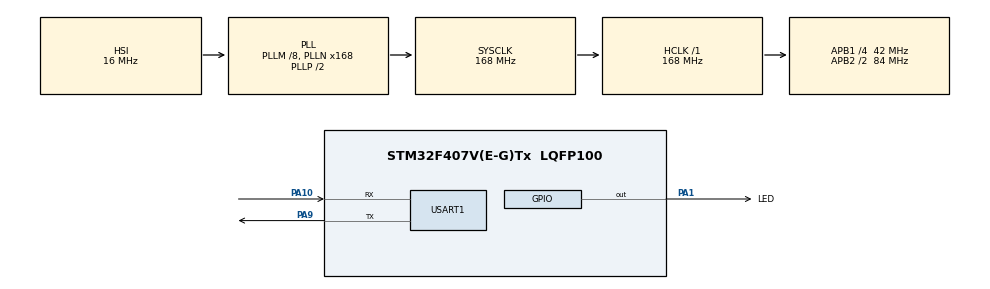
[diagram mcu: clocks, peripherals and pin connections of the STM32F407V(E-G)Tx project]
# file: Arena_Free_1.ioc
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Dma.Request0=USART1_RX
Dma.Request1=USART1_TX
Dma.USART1_RX.0.Direction=DMA_PERIPH_TO_MEMORY
Dma.USART1_RX.0.FIFOMode=DMA_FIFOMODE_DISABLE
Dma.USART1_RX.0.Instance=DMA2_Stream2
Dma.USART1_RX.0.MemDataAlignment=DMA_MDATAALIGN_BYTE
Dma.USART1_RX.0.MemInc=DMA_MINC_ENABLE
Dma.USART1_RX.0.Mode=DMA_CIRCULAR
Dma.USART1_RX.0.PeriphDataAlignment=DMA_PDATAALIGN_BYTE
Dma.USART1_RX.0.PeriphInc=DMA_PINC_DISABLE
Dma.USART1_RX.0.Priority=DMA_PRIORITY_LOW
Dma.USART1_TX.1.Direction=DMA_MEMORY_TO_PERIPH
Dma.USART1_TX.1.FIFOMode=DMA_FIFOMODE_DISABLE
Dma.USART1_TX.1.Instance=DMA2_Stream7
Dma.USART1_TX.1.MemDataAlignment=DMA_MDATAALIGN_BYTE
Dma.USART1_TX.1.MemInc=DMA_MINC_ENABLE
Dma.USART1_TX.1.Mode=DMA_NORMAL
Dma.USART1_TX.1.PeriphDataAlignment=DMA_PDATAALIGN_BYTE
Dma.USART1_TX.1.PeriphInc=DMA_PINC_DISABLE
Dma.USART1_TX.1.Priority=DMA_PRIORITY_LOW
FREERTOS.Tasks01=LEDTask,0,128,LEDtTask,Default,NULL,Dynamic,NULL,NULL
Mcu.Family=STM32F4
Mcu.Name=STM32F407V(E-G)Tx
Mcu.Package=LQFP100
NVIC.DMA2_Stream2_IRQn=true\:0\:0\:false\:false\:true\:true\:false\:true
NVIC.DMA2_Stream7_IRQn=true\:0\:0\:false\:false\:true\:true\:false\:true
NVIC.PriorityGroup=NVIC_PRIORITYGROUP_4
NVIC.TIM8_TRG_COM_TIM14_IRQn=true\:0\:0\:false\:false\:true\:false\:false\:true
NVIC.TimeBase=TIM8_TRG_COM_TIM14_IRQn
NVIC.TimeBaseIP=TIM14
NVIC.USART1_IRQn=true\:0\:0\:false\:false\:true\:true\:true\:true
PA1.GPIO_Label=LED
PA1.Signal=GPIO_Output
PA10.Mode=Asynchronous
PA10.Signal=USART1_RX
PA13.Mode=Serial_Wire
PA13.Signal=SYS_JTMS-SWDIO
PA14.Mode=Serial_Wire
PA14.Signal=SYS_JTCK-SWCLK
PA9.Mode=Asynchronous
PA9.Signal=USART1_TX
PH0-OSC_IN.Mode=HSE-External-Oscillator
PH0-OSC_IN.Signal=RCC_OSC_IN
PH1-OSC_OUT.Mode=HSE-External-Oscillator
PH1-OSC_OUT.Signal=RCC_OSC_OUT
ProjectManager.HeapSize=0x200
ProjectManager.StackSize=0x400
ProjectManager.TargetToolchain=STM32CubeIDE
RCC.48MHZClocksFreq_Value=84000000
RCC.AHBFreq_Value=168000000
RCC.APB1CLKDivider=RCC_HCLK_DIV4
RCC.APB1Freq_Value=42000000
RCC.APB1TimFreq_Value=84000000
RCC.APB2CLKDivider=RCC_HCLK_DIV2
RCC.APB2Freq_Value=84000000
RCC.APB2TimFreq_Value=168000000
RCC.CortexFreq_Value=168000000
RCC.HCLKFreq_Value=168000000
RCC.HSE_VALUE=25000000
RCC.HSI_VALUE=16000000
RCC.LSE_VALUE=32768
RCC.PLLM=8
RCC.PLLN=168
RCC.SYSCLKFreq_VALUE=168000000
RCC.SYSCLKSource=RCC_SYSCLKSOURCE_PLLCLK
RCC.VCOOutputFreq_Value=336000000
USART1.VirtualMode=VM_ASYNC
VP_FREERTOS_VS_CMSIS_V1.Mode=CMSIS_V1
VP_SYS_VS_tim14.Mode=TIM14
board=custom

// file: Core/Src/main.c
/* USER CODE BEGIN Header */
/**
 ******************************************************************************
 * @file           : main.c
 * @brief          : Main program body
 ******************************************************************************
 * @attention
 *
 * <h2><center>&copy; Copyright (c) 2020 STMicroelectronics.
 * All rights reserved.</center></h2>
 *
 * This software component is licensed by ST under BSD 3-Clause license,
 * the "License"; You may not use this file except in compliance with the
 * License. You may obtain a copy of the License at:
 *                        opensource.org/licenses/BSD-3-Clause
 *
 ******************************************************************************
 */
/* USER CODE END Header */
#include "main.h"
#include "cmsis_os.h"

/* USER CODE BEGIN Includes */

#include "macro.h"

/* USER CODE END Includes */

UART_HandleTypeDef huart1;
DMA_HandleTypeDef hdma_usart1_rx;
DMA_HandleTypeDef hdma_usart1_tx;

osThreadId LEDTaskHandle;

void SystemClock_Config(void);
static void MX_GPIO_Init(void);
static void MX_DMA_Init(void);
static void MX_USART1_UART_Init(void);
void LEDtTask(const void *argument);

int main(void)
{

	/* MCU Configuration--------------------------------------------------------*/

	/* Reset of all peripherals, Initializes the Flash interface and the Systick. */
	HAL_Init();

	/* Configure the system clock */
	SystemClock_Config();

	/* Initialize all configured peripherals */
	MX_GPIO_Init();
	MX_DMA_Init();
	MX_USART1_UART_Init();
	/* USER CODE BEGIN 2 */

	bluetooth_DMA(&huart1);

	/* USER CODE END 2 */

	/* Create the thread(s) */
	/* definition and creation of LEDTask */
	osThreadDef(LEDTask, LEDtTask, osPriorityNormal, 0, 128);
	LEDTaskHandle = osThreadCreate(osThread(LEDTask), NULL);

	/* Start scheduler */
	osKernelStart();

	/* We should never get here as control is now taken by the scheduler */
	/* Infinite loop */
	while (1)
	{

	}
}

void SystemClock_Config(void)
{
	RCC_OscInitTypeDef RCC_OscInitStruct =
	{ 0 };
	RCC_ClkInitTypeDef RCC_ClkInitStruct =
	{ 0 };

	/** Configure the main internal regulator output voltage
	 */
	__HAL_RCC_PWR_CLK_ENABLE();
	__HAL_PWR_VOLTAGESCALING_CONFIG(PWR_REGULATOR_VOLTAGE_SCALE1);
	/** Initializes the RCC Oscillators according to the specified parameters
	 * in the RCC_OscInitTypeDef structure.
	 */
	RCC_OscInitStruct.OscillatorType = RCC_OSCILLATORTYPE_HSI;
	RCC_OscInitStruct.HSIState = RCC_HSI_ON;
	RCC_OscInitStruct.HSICalibrationValue = RCC_HSICALIBRATION_DEFAULT;
	RCC_OscInitStruct.PLL.PLLState = RCC_PLL_ON;
	RCC_OscInitStruct.PLL.PLLSource = RCC_PLLSOURCE_HSI;
	RCC_OscInitStruct.PLL.PLLM = 8;
	RCC_OscInitStruct.PLL.PLLN = 168;
	RCC_OscInitStruct.PLL.PLLP = RCC_PLLP_DIV2;
	RCC_OscInitStruct.PLL.PLLQ = 4;
	if (HAL_RCC_OscConfig(&RCC_OscInitStruct) != HAL_OK)
	{
		Error_Handler();
	}
	/** Initializes the CPU, AHB and APB buses clocks
	 */
	RCC_ClkInitStruct.ClockType = RCC_CLOCKTYPE_HCLK | RCC_CLOCKTYPE_SYSCLK
			| RCC_CLOCKTYPE_PCLK1 | RCC_CLOCKTYPE_PCLK2;
	RCC_ClkInitStruct.SYSCLKSource = RCC_SYSCLKSOURCE_PLLCLK;
	RCC_ClkInitStruct.AHBCLKDivider = RCC_SYSCLK_DIV1;
	RCC_ClkInitStruct.APB1CLKDivider = RCC_HCLK_DIV4;
	RCC_ClkInitStruct.APB2CLKDivider = RCC_HCLK_DIV2;

	if (HAL_RCC_ClockConfig(&RCC_ClkInitStruct, FLASH_LATENCY_5) != HAL_OK)
	{
		Error_Handler();
	}
}

static void MX_USART1_UART_Init(void)
{

	huart1.Instance = USART1;
	huart1.Init.BaudRate = 115200;
	huart1.Init.WordLength = UART_WORDLENGTH_8B;
	huart1.Init.StopBits = UART_STOPBITS_1;
	huart1.Init.Parity = UART_PARITY_NONE;
	huart1.Init.Mode = UART_MODE_TX_RX;
	huart1.Init.HwFlowCtl = UART_HWCONTROL_NONE;
	huart1.Init.OverSampling = UART_OVERSAMPLING_16;
	if (HAL_UART_Init(&huart1) != HAL_OK)
	{
		Error_Handler();
	}

}

static void MX_DMA_Init(void)
{

	/* DMA controller clock enable */
	__HAL_RCC_DMA2_CLK_ENABLE();

	/* DMA interrupt init */
	/* DMA2_Stream2_IRQn interrupt configuration */
	HAL_NVIC_SetPriority(DMA2_Stream2_IRQn, 0, 0);
	HAL_NVIC_EnableIRQ(DMA2_Stream2_IRQn);
	/* DMA2_Stream7_IRQn interrupt configuration */
	HAL_NVIC_SetPriority(DMA2_Stream7_IRQn, 0, 0);
	HAL_NVIC_EnableIRQ(DMA2_Stream7_IRQn);

}

static void MX_GPIO_Init(void)
{
	GPIO_InitTypeDef GPIO_InitStruct =
	{ 0 };

	/* GPIO Ports Clock Enable */
	__HAL_RCC_GPIOH_CLK_ENABLE();
	__HAL_RCC_GPIOA_CLK_ENABLE();

	/*Configure GPIO pin Output Level */
	HAL_GPIO_WritePin(LED_GPIO_Port, LED_Pin, GPIO_PIN_RESET);

	/*Configure GPIO pin : LED_Pin */
	GPIO_InitStruct.Pin = LED_Pin;
	GPIO_InitStruct.Mode = GPIO_MODE_OUTPUT_PP;
	GPIO_InitStruct.Pull = GPIO_NOPULL;
	GPIO_InitStruct.Speed = GPIO_SPEED_FREQ_LOW;
	HAL_GPIO_Init(LED_GPIO_Port, &GPIO_InitStruct);

}

void LEDtTask(const void *argument)
{
	for (;;)
	{
	}
}

void HAL_TIM_PeriodElapsedCallback(TIM_HandleTypeDef *htim)
{
	if (htim->Instance == TIM14)
	{
		HAL_IncTick();
	}
}

void Error_Handler(void)
{
}

/************************ (C) COPYRIGHT STMicroelectronics *****END OF FILE****/
